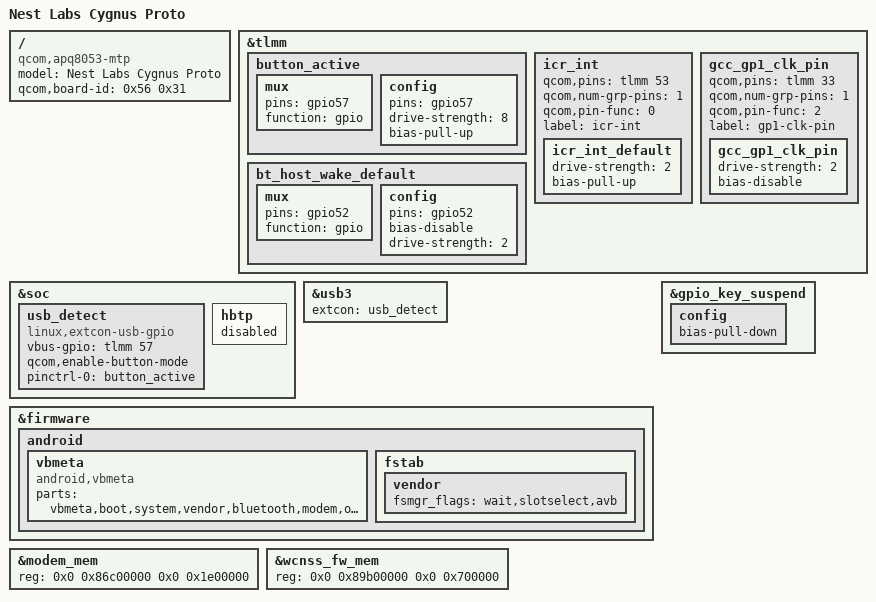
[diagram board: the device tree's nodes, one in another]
/dts-v1/;

#include "cygnus-apq8053.dtsi"
#include "apq8053-camera-sensor-mtp.dtsi"
#include "cygnus-regulator.dtsi"
#include "cygnus.dtsi"

/ {
	model = "Nest Labs Cygnus Proto";
	compatible = "qcom,apq8053-mtp", "qcom,apq8053", "qcom,mtp", "nest,cygnus";
	qcom,board-id= <0x56 0x31>;
};

&tlmm {
	button_active: button_active {
		mux {
			pins = "gpio57";
			function = "gpio";
		};

		config {
			pins = "gpio57";
			drive-strength = <8>;
			bias-pull-up;
		};
	};

	icr_int {
		qcom,pins = <&tlmm 53>;
		qcom,num-grp-pins = <1>;
		qcom,pin-func = <0>;
		label = "icr-int";
		icr_int_default: icr_int_default {
			drive-strength = <2>;	/* 2 MA */
			bias-pull-up;		/* PULL UP*/
		};
	};

	gcc_gp1_clk_pin {
		qcom,pins = <&tlmm 33>;
		qcom,num-grp-pins = <1>;
		qcom,pin-func = <2>;
		label = "gp1-clk-pin";
		gcc_gp1_clk_pin: gcc_gp1_clk_pin {
			drive-strength = <2>;	/* 2 MA */
			bias-disable;
		};
	};

	bt_host_wake_default: bt_host_wake_default {
		mux {
			pins = "gpio52";
                        function = "gpio";
                };
                config {
                	pins = "gpio52";
                        bias-disable; /* No PULL */
                        drive-strength = <2>;
                };
         };
};

&soc {
	usb_detect: usb_detect {
		compatible = "linux,extcon-usb-gpio";
		vbus-gpio = <&tlmm 57 GPIO_ACTIVE_HIGH>;
		qcom,enable-button-mode;
		pinctrl-names = "button_active";
		pinctrl-0 = <&button_active>;
	};

	hbtp {
		status = "disabled";
	};
};

&usb3 {
	extcon = <&usb_detect>;
};

&firmware {
 	android {
		vbmeta {
			compatible = "android,vbmeta";
			parts = "vbmeta,boot,system,vendor,bluetooth,modem,oem";
		};
		fstab {
			/delete-node/ system;
			vendor {
				fsmgr_flags = "wait,slotselect,avb";
			};
		};
	};
};

&modem_mem {
	reg = <0x0 0x86c00000 0x0 0x1e00000>;
};

&wcnss_fw_mem {
	reg = <0x0 0x89b00000 0x0 0x700000>;
};

&gpio_key_suspend {
	config {
		/delete-property/ bias-pull-up;
		bias-pull-down;
	};
};
